# ADC_ADC_CFG_502C0000h register map
Vendor: Texas Instruments
Registers are 16-bit, read-write, reset values left out (the file's numbers can be read two ways) unless marked. A register's access mark holds for its fields unless they carry their own. Offsets are as the file gives them; [hi:lo] are bit positions; {n}, {i} and the like mark numbered series.

## ADC_CFG (part 2 of 3)
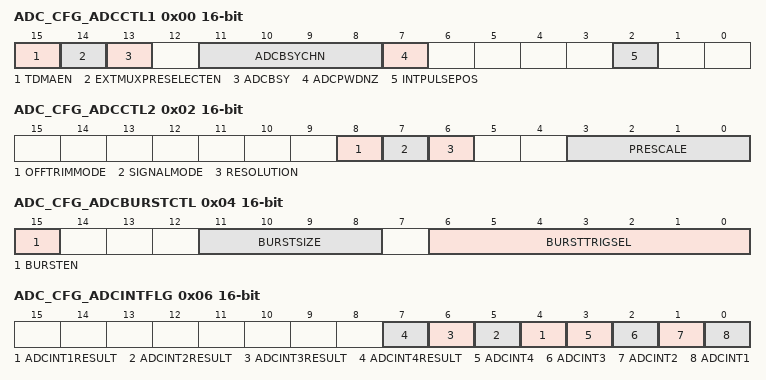
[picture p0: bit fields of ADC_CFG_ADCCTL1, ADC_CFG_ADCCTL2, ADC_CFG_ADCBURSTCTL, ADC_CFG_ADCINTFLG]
0x00 ADC_CFG_ADCCTL1 access per field — ADC Control 1 Register.
  [15] TDMAEN rw — Enable Alternate DMA Timings. This bit controls when the DMA is triggered. 0 DMA is triggered at the same time as the CPU interrupt 1 DMA is always triggered at tDMA regardless or whether the ADC is in early interrupt mode or late interrupt mode
  [14] EXTMUXPRESELECTEN rw — If th the ADC SOC sequence is deterministic, the ADCEXTMUX pins can be set earlier: at the end of the S+H window of the previous conversion instead of the beginning of the S+H window of the current conversion. This allows some of the external mux settling time to be pipelined with the previous conversion's conversion time. However, this will not work in the case where high-priority SOCs can arrive asynchronously. 0 ADCEXTMUX pins only change at beginning of S+H window 1 ADCEXTMUX pins are set after the end of S+H window based on pending SOCs
  [13] ADCBSY ro — ADC Busy. Set when ADC SOC is generated, cleared by hardware four ADC clocks after negative edge of S/H pulse. Used by the ADC state machine to determine if ADC is available to sample. 0 ADC is available to sample next channel 1 ADC is busy and cannot sample another channel
  [11:8] ADCBSYCHN ro — ADC Busy Channel. Set when an ADC Start of Conversion [SOC] is generated. When ADCBSY0:holds the value of the last converted SOC When ADCBSY1:reflects the SOC currently being processed 0h SOC0 is currently processing or was last SOC converted 1h SOC1 is currently processing or was last SOC converted 2h SOC2 is currently processing or was last SOC converted 3h SOC3 is currently processing or was last SOC converted 4h SOC4 is currently processing or was last SOC converted 5h SOC5 is currently processing or was last SOC converted 6h SOC6 is currently processing or was last SOC converted 7h SOC7 is currently processing or was last SOC converted 8h SOC8 is currently processing or was last SOC converted 9h SOC9 is currently processing or was last SOC converted Ah SOC10 is currently processing or was last SOC converted Bh SOC11 is currently processing or was last SOC converted Ch SOC12 is currently processing or was last SOC converted Dh SOC13 is currently processing or was last SOC converted Eh SOC14 is currently processing or was last SOC converted Fh SOC15 is currently processing or was last SOC converted
  [7] ADCPWDNZ rw — ADC Power Down [active low]. This bit controls the power up and power down of all the analog circuitry inside the analog core. 0 All analog circuitry inside the core is powered down 1 All analog circuitry inside the core is powered up
  [2] INTPULSEPOS rw — ADC Interrupt Pulse Position. 0 Interrupt pulse generation occurs when ADC begins conversion [at the end of the acquisition window] plus a number of SYSCLK cycles as specified in the ADCINTCYCLE.OFFSET register. 1 Interrupt pulse generation occurs at the end of the conversion, 1 cycle prior to the ADC result latching into its result register
0x02 ADC_CFG_ADCCTL2 — ADC Control 2 Register.
  [8] OFFTRIMMODE — ADC offset trim mode. 0 = Offset trim supplied by ADCOFFTRIM.OFFTRIM regardless of resolution or signal mode 1 = Offset trim for each combination of resolution, signalmode, and even or odd is supplied by a different field in ADCOFFTRIM, ADCOFFTRIM2, or ADCOFFTRIM3
  [7] SIGNALMODE — SOC Signaling Mode. Selects the input mode of the converter. Use the AdcSetMode function to change the signal mode. 0 Single-ended 1 Differential
  [6] RESOLUTION — SOC Conversion Resolution. Selects the resolution of the converter. Use the AdcSetMode function to change the resolution. 0 12-bit resolution
  [3:0] PRESCALE — ADC Clock Prescaler. 0000 ADCCLK = Input Clock / 1.0 0001 Invalid 0010 ADCCLK = Input Clock / 2.0 0011 ADCCLK = Input Clock / 2.5 0100 ADCCLK = Input Clock / 3.0 0101 ADCCLK = Input Clock / 3.5 0110 ADCCLK = Input Clock / 4.0 0111 ADCCLK = Input Clock / 4.5 1000 ADCCLK = Input Clock / 5.0 1001 ADCCLK = Input Clock / 5.5 1010 ADCCLK = Input Clock / 6.0 1011 ADCCLK = Input Clock / 6.5 1100 ADCCLK = Input Clock / 7.0 1101 ADCCLK = Input Clock / 7.5 1110 ADCCLK = Input Clock / 8.0 1111 ADCCLK = Input Clock / 8.5
0x04 ADC_CFG_ADCBURSTCTL — ADC Burst Control Register.
  [15] BURSTEN — SOC Burst Mode Enable. This bit enables the SOC Burst Mode of operation. 0 Burst mode is disabled. 1 Burst mode is enabled.
  [11:8] BURSTSIZE — SOC Burst Size Select. This bit field determines how many SOCs are converted when a burst conversion sequence is started. The first SOC converted is defined by the round robin pointer, which is advanced as each SOC is converted. 0h 1 SOC converted 1h 2 SOCs converted 2h 3 SOCs converted 3h 4 SOCs converted 4h 5 SOCs converted 5h 6 SOCs converted 6h 7 SOCs converted 7h 8 SOCs converted 8h 9 SOCs converted 9h 10 SOCs converted Ah 11 SOCs converted Bh 12 SOCs converted Ch 13 SOCs converted Dh 14 SOCs converted Eh 15 SOCs converted Fh 16 SOCs converted Note: If the burst causes SOCs to be set for conversion that were already pending, the corresponding bits in the ADCSOCOVF register will be set.
  [6:0] BURSTTRIGSEL — SOC Burst Trigger Source Select. Configures which trigger will start a burst conversion sequence.Note: SOCFRC1 register can always be used to software trigger SOCs in addition to any hardware trigger configuration. 00h BURSTTRIG0 - Software only 01h BURSTTRIG1 - RTI0 Timer 02h BURSTTRIG2 - RTI1 Timer 03h BURSTTRIG3 - RTI2 Timer 04h BURSTTRIG4 - RTI3 Timer 05h BURSTTRIG5 - InputXBAR.Out[5] 06h BURSTTRIG6 - spare 07h BURSTTRIG7 - spare 08h BURSTTRIG8 - EPWM0, ADCSOCA 09h BURSTTRIG9 - EPWM0, ADCSOCB 0Ah BURSTTRIG10 - EPWM1, ADCSOCA 0Bh BURSTTRIG11 - EPWM1, ADCSOCB 0Ch BURSTTRIG12 - EPWM2, ADCSOCA 0Dh BURSTTRIG13 - EPWM2, ADCSOCB 0Eh BURSTTRIG14 - EPWM3, ADCSOCA 0Fh BURSTTRIG15 - EPWM3, ADCSOCB .... EPWM4 to EPWM27 40h BURSTTRIG64 - EPWM28, ADCSOCA 41h BURSTTRIG65 - EPWM28, ADCSOCB 42h BURSTTRIG66 - EPWM29, ADCSOCA 43h BURSTTRIG67 - EPWM29, ADCSOCB 44h BURSTTRIG68 - EPWM30, ADCSOCA 45h BURSTTRIG69 - EPWM30, ADCSOCB 46h BURSTTRIG70 - EPWM31, ADCSOCA 47h BURSTTRIG71 - EPWM31, ADCSOCB 48h BURSTTRIG72 - ECAP0, TRIGOUT .... ECAP1 to ECAP8 51h BURSTTRIG81 - ECAP9, TRIGOUT 52h BURSTTRIG82 - ECAP10, TRIGOUT .... 57h BURSTTRIG73 - ECAP15, TRIGOUT 58h BURSTTRIG1 - RTI4 Timer 59h BURSTTRIG1 - RTI5 Timer 5Ah BURSTTRIG1 - RTI6 Timer 5Bh BURSTTRIG1 - RTI7 Timer
0x06 ADC_CFG_ADCINTFLG ro — ADC Interrupt Flag Register.
  [n+3] ADCINT{n}RESULT (n=1..4) — ADC Interrupt {n} Results Ready Flag. This flag is set when the conversions results associated with ADCINT{n} latch into the corresponding results register. 0 Conversion results have not latched 1 Conversion results have latched This flag can be used in an ISR that is entered in early interrupt mode to ensure that the corresponding results are ready before proceeding to read the result register. This flag can be cleared via the ACK bit in the ADCINTFLGCLR that also clears the ADCINT{n} flag. In case results latch and this flag is already set, the corresponding flag in ADCINTOVF is NOT set. This flag does NOT have to be cleared in order for ADCINT ISRs to propagate to the PIE. In case the associated SOC is associated with a PPB or PPBs, the flag will not be set until all associated PPB results latch.
  [3] ADCINT4 — ADC Interrupt 4 Flag. Reading these flags indicates if the associated ADCINT pulse was generated since the last clear. 0 No ADC interrupt pulse generated 1 ADC interrupt pulse generated If the ADC interrupt is placed in continue to interrupt mode [INTSELxNy register] then further interrupt pulses are generated whenever a selected EOC event occurs even if the flag bit is set. If the continuous mode is not enabled, then no further interrupt pulses are generated until the user clears this flag bit using the ADCINFLGCLR register. Rather, an ADC interrupt overflow event occurs in the ADCINTOVF register.
  [2] ADCINT3 — ADC Interrupt 3 Flag. Reading these flags indicates if the associated ADCINT pulse was generated since the last clear. 0 No ADC interrupt pulse generated 1 ADC interrupt pulse generated If the ADC interrupt is placed in continue to interrupt mode [INTSELxNy register] then further interrupt pulses are generated whenever a selected EOC event occurs even if the flag bit is set. If the continuous mode is not enabled, then no further interrupt pulses are generated until the user clears this flag bit using the ADCINTFLGCLR register. Rather, an ADC interrupt overflow event occurs in the ADCINTOVF register.
  [1] ADCINT2 — ADC Interrupt 2 Flag. Reading these flags indicates if the associated ADCINT pulse was generated since the last clear. 0 No ADC interrupt pulse generated 1 ADC interrupt pulse generated If the ADC interrupt is placed in continue to interrupt mode [INTSELxNy register] then further interrupt pulses are generated whenever a selected EOC event occurs even if the flag bit is set. If the continuous mode is not enabled, then no further interrupt pulses are generated until the user clears this flag bit using the ADCINTFLGCLR register. Rather, an ADC interrupt overflow event occurs in the ADCINTOVF register.
  [0] ADCINT1 — ADC Interrupt 1 Flag. Reading these flags indicates if the associated ADCINT pulse was generated since the last clear. 0 No ADC interrupt pulse generated 1 ADC interrupt pulse generated If the ADC interrupt is placed in continue to interrupt mode [INTSELxNy register] then further interrupt pulses are generated whenever a selected EOC event occurs even if the flag bit is set. If the continuous mode is not enabled, then no further interrupt pulses are generated until the user clears this flag bit using the ADCINTFLGCLR register. Rather, an ADC interrupt overflow event occurs in the ADCINTOVF register.
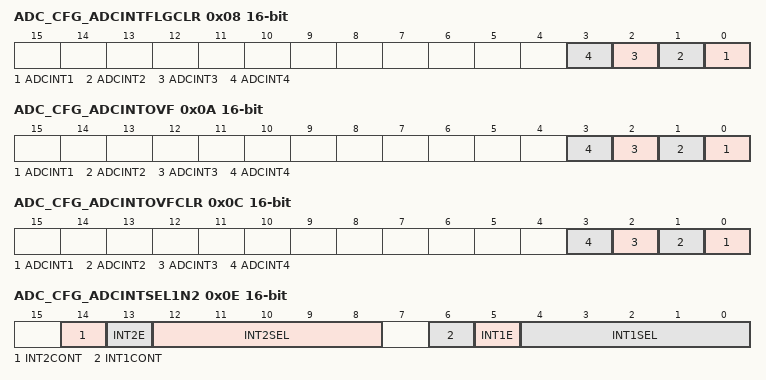
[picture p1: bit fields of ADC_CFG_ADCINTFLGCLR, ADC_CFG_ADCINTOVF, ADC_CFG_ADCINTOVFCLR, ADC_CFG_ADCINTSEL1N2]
0x08 ADC_CFG_ADCINTFLGCLR access not given — ADC Interrupt Flag Clear Register.
  [n-1] ADCINT{n} (n=1..4) — ADC Interrupt {n} Flag Clear. Reads return 0. 0 No action 1 Clears respective flag bit in the ADCINTFLG register. If software sets the clear bit on the same cycle that hardware is trying to set the flag bit, then hardware has priority and the overflow bit will not be set (access R/W1TS)
0x0A ADC_CFG_ADCINTOVF ro — ADC Interrupt Overflow Register.
  [n-1] ADCINT{n} (n=1..4) — ADC Interrupt {n} Overflow Flags Indicates if an overflow occurred when generating ADCINT pulses. If the respective ADCINTFLG bit is set and a selected additional EOC trigger is generated, then an overflow condition occurs. 0 No ADC interrupt overflow event detected. 1 ADC Interrupt overflow event detected. The overflow bit does not care about the continuous mode bit state. An overflow condition is generated irrespective of this mode selection.
0x0C ADC_CFG_ADCINTOVFCLR access not given — ADC Interrupt Overflow Clear Register.
  [n-1] ADCINT{n} (n=1..4) — ADC Interrupt {n} Overflow Clear Bits 0 No action. 1 Clears the respective overflow bit in the ADCINTOVF register. If software tries to set this bit on the same clock cycle that hardware tries to set the overflow bit in the ADCINTOVF register, then hardware has priority and the ADCINTOVF bit will be set. (access R/W1TS)
0x0E ADC_CFG_ADCINTSEL1N2 — ADC Interrupt 1 and 2 Selection Register.
  [14] INT2CONT — ADCINT2 Continue to Interrupt Mode 0 No further ADCINT2 pulses are generated until ADCINT2 flag [in ADCINTFLG register] is cleared by user. 1 ADCINT2 pulses are generated whenever an EOC pulse is generated irrespective of whether the flag bit is cleared or not.
  [13] INT2E — ADCINT2 Interrupt Enable 0 ADCINT2 is disabled 1 ADCINT2 is enabled
  [12:8] INT2SEL — ADCINT2 EOC Source Select 00h EOC0 is trigger for ADCINT2 01h EOC1 is trigger for ADCINT2 02h EOC2 is trigger for ADCINT2 03h EOC3 is trigger for ADCINT2 04h EOC4 is trigger for ADCINT2 05h EOC5 is trigger for ADCINT2 06h EOC6 is trigger for ADCINT2 07h EOC7 is trigger for ADCINT2 08h EOC8 is trigger for ADCINT2 09h EOC9 is trigger for ADCINT2 0Ah EOC10 is trigger for ADCINT2 0Bh EOC11 is trigger for ADCINT2 0Ch EOC12 is trigger for ADCINT2 0Dh EOC13 is trigger for ADCINT2 0Eh EOC14 is trigger for ADCINT2 0Fh EOC15 is trigger for ADCINT2 10h OSINT1 is trigger for ADCINT2 11h OSINT2 is trigger for ADCINT2 12h OSINT3 is trigger for ADCINT2 13h OSINT4 is trigger for ADCINT2
  [6] INT1CONT — ADCINT1 Continue to Interrupt Mode 0 No further ADCINT1 pulses are generated until ADCINT1 flag [in ADCINTFLG register] is cleared by user. 1 ADCINT1 pulses are generated whenever an EOC pulse is generated irrespective of whether the flag bit is cleared or not.
  [5] INT1E — ADCINT1 Interrupt Enable 0 ADCINT1 is disabled 1 ADCINT1 is enabled
  [4:0] INT1SEL — ADCINT1 EOC Source Select 00h EOC0 is trigger for ADCINT1 01h EOC1 is trigger for ADCINT1 02h EOC2 is trigger for ADCINT1 03h EOC3 is trigger for ADCINT1 04h EOC4 is trigger for ADCINT1 05h EOC5 is trigger for ADCINT1 06h EOC6 is trigger for ADCINT1 07h EOC7 is trigger for ADCINT1 08h EOC8 is trigger for ADCINT1 09h EOC9 is trigger for ADCINT1 0Ah EOC10 is trigger for ADCINT1 0Bh EOC11 is trigger for ADCINT1 0Ch EOC12 is trigger for ADCINT1 0Dh EOC13 is trigger for ADCINT1 0Eh EOC14 is trigger for ADCINT1 0Fh EOC15 is trigger for ADCINT1 10h OSINT1 is trigger for ADCINT1 11h OSINT2 is trigger for ADCINT1 12h OSINT3 is trigger for ADCINT1 13h OSINT4 is trigger for ADCINT1
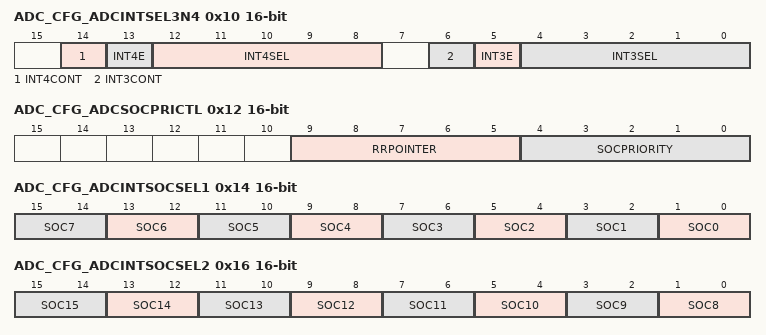
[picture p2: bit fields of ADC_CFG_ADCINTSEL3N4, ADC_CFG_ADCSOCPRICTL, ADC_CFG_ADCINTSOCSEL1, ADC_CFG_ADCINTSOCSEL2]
0x10 ADC_CFG_ADCINTSEL3N4 — ADC Interrupt 3 and 4 Selection Register.
  [14] INT4CONT — ADCINT4 Continue to Interrupt Mode 0 No further ADCINT4 pulses are generated until ADCINT4 flag [in ADCINTFLG register] is cleared by user. 1 ADCINT4 pulses are generated whenever an EOC pulse is generated irrespective of whether the flag bit is cleared or not.
  [13] INT4E — ADCINT4 Interrupt Enable 0 ADCINT4 is disabled 1 ADCINT4 is enabled
  [12:8] INT4SEL — ADCINT4 EOC Source Select 00h EOC0 is trigger for ADCINT4 01h EOC1 is trigger for ADCINT4 02h EOC2 is trigger for ADCINT4 03h EOC3 is trigger for ADCINT4 04h EOC4 is trigger for ADCINT4 05h EOC5 is trigger for ADCINT4 06h EOC6 is trigger for ADCINT4 07h EOC7 is trigger for ADCINT4 08h EOC8 is trigger for ADCINT4 09h EOC9 is trigger for ADCINT4 0Ah EOC10 is trigger for ADCINT4 0Bh EOC11 is trigger for ADCINT4 0Ch EOC12 is trigger for ADCINT4 0Dh EOC13 is trigger for ADCINT4 0Eh EOC14 is trigger for ADCINT4 0Fh EOC15 is trigger for ADCINT4 10hOSINT1 is trigger for ADCINT4 11hOSINT2 is trigger for ADCINT4 12hOSINT3 is trigger for ADCINT4 13hOSINT4 is trigger for ADCINT4
  [6] INT3CONT — ADCINT3 Continue to Interrupt Mode 0 No further ADCINT3 pulses are generated until ADCINT3 flag [in ADCINTFLG register] is cleared by user. 1 ADCINT3 pulses are generated whenever an EOC pulse is generated irrespective of whether the flag bit is cleared or not.
  [5] INT3E — ADCINT3 Interrupt Enable 0 ADCINT3 is disabled 1 ADCINT3 is enabled
  [4:0] INT3SEL — ADCINT3 EOC Source Select 00h EOC0 is trigger for ADCINT3 01h EOC1 is trigger for ADCINT3 02h EOC2 is trigger for ADCINT3 03h EOC3 is trigger for ADCINT3 04h EOC4 is trigger for ADCINT3 05h EOC5 is trigger for ADCINT3 06h EOC6 is trigger for ADCINT3 07h EOC7 is trigger for ADCINT3 08h EOC8 is trigger for ADCINT3 09h EOC9 is trigger for ADCINT3 0Ah EOC10 is trigger for ADCINT3 0Bh EOC11 is trigger for ADCINT3 0Ch EOC12 is trigger for ADCINT3 0Dh EOC13 is trigger for ADCINT3 0Eh EOC14 is trigger for ADCINT3 0Fh EOC15 is trigger for ADCINT3 10h OSINT1 is trigger for ADCINT3 11h OSINT2 is trigger for ADCINT3 12h OSINT3 is trigger for ADCINT3 13h OSINT4 is trigger for ADCINT3
0x12 ADC_CFG_ADCSOCPRICTL access per field — ADC SOC Priority Control Register.
  [9:5] RRPOINTER ro — Round Robin Pointer. Holds the value of the last converted round robin SOCx to be used by the round robin scheme to determine order of conversions. 00h SOC0 was last round robin SOC to convert, SOC1 is highest round robin priority. 01h SOC1 was last round robin SOC to convert, SOC2 is highest round robin priority. 02h SOC2 was last round robin SOC to convert, SOC3 is highest round robin priority. 03h SOC3 was last round robin SOC to convert, SOC4 is highest round robin priority. 04h SOC4 was last round robin SOC to convert, SOC5 is highest round robin priority. 05h SOC5 was last round robin SOC to convert, SOC6 is highest round robin priority. 06h SOC6 was last round robin SOC to convert, SOC7 is highest round robin priority. 07h SOC7 was last round robin SOC to convert, SOC8 is highest round robin priority. 08h SOC8 was last round robin SOC to convert, SOC9 is highest round robin priority. 09h SOC9 was last round robin SOC to convert, SOC10 is highest round robin priority. 0Ah SOC10 was last round robin SOC to convert, SOC11 is highest round robin priority. 0Bh SOC11 was last round robin SOC to convert, SOC12 is highest round robin priority. 0Ch SOC12 was last round robin SOC to convert, SOC13 is highest round robin priority. 0Dh SOC13 was last round robin SOC to convert, SOC14 is highest round robin priority. 0Eh SOC14 was last round robin SOC to convert, SOC15 is highest round robin priority. 0Fh SOC15 was last round robin SOC to convert, SOC0 is highest round robin priority. 10h Reset value to indicate no SOC has been converted. SOC0 is highest round robin priority. Set to this value when the ADC module is reset by SOFTPRES or when the ADCSOCPRICTL register is written. In the latter case, if a conversion is currently in progress, it will complete and then the new priority will take effect. Others Invalid value.
  [4:0] SOCPRIORITY rw — SOC Priority Determines the cutoff point for priority mode and round robin arbitration for SOCx 00h SOC priority is handled in round robin mode for all channels. 01h SOC0 is high priority, rest of channels are in round robin mode. 02h SOC0-SOC1 are high priority, SOC2-SOC15 are in round robin mode. 03h SOC0-SOC2 are high priority, SOC3-SOC15 are in round robin mode. 04h SOC0-SOC3 are high priority, SOC4-SOC15 are in round robin mode. 05h SOC0-SOC4 are high priority, SOC5-SOC15 are in round robin mode. 06h SOC0-SOC5 are high priority, SOC6-SOC15 are in round robin mode. 07h SOC0-SOC6 are high priority, SOC7-SOC15 are in round robin mode. 08h SOC0-SOC7 are high priority, SOC8-SOC15 are in round robin mode. 09h SOC0-SOC8 are high priority, SOC9-SOC15 are in round robin mode. 0Ah SOC0-SOC9 are high priority, SOC10-SOC15 are in round robin mode. 0Bh SOC0-SOC10 are high priority, SOC11-SOC15 are in round robin mode. 0Ch SOC0-SOC11 are high priority, SOC12-SOC15 are in round robin mode. 0Dh SOC0-SOC12 are high priority, SOC13-SOC15 are in round robin mode. 0Eh SOC0-SOC13 are high priority, SOC14-SOC15 are in round robin mode. 0Fh SOC0-SOC14 are high priority, SOC15 is in round robin mode. 10h All SOCs are in high priority mode, arbitrated by SOC number. Others Invalid selection.
0x14 ADC_CFG_ADCINTSOCSEL1 — ADC Interrupt SOC Selection 1 Register.
  [2n+1:2n] SOC{n} (n=0..7) — SOC{n} ADC Interrupt Trigger Select. Selects which, if any, ADCINT triggers SOC{n}. The trigger selected in this field is in addition to the TRIGSEL field in the ADCSOCxCTL register. 00 No ADCINT will trigger SOC{n}. TRIGSEL field alone determines SOC0 trigger. 01 ADCINT1 will trigger SOC{n}. 10 ADCINT2 will trigger SOC{n}. 11 Invalid selection.
0x16 ADC_CFG_ADCINTSOCSEL2 — ADC Interrupt SOC Selection 2 Register.
  [2n-15:2n-16] SOC{n} (n=8..15) — SOC{n} ADC Interrupt Trigger Select. Selects which, if any, ADCINT triggers SOC{n}. The trigger selected in this field is in addition to the TRIGSEL field in the ADCSOCxCTL register. 00 No ADCINT will trigger SOC{n}. TRIGSEL field alone determines SOC0 trigger. 01 ADCINT1 will trigger SOC{n}. 10 ADCINT2 will trigger SOC{n}. 11 Invalid selection.
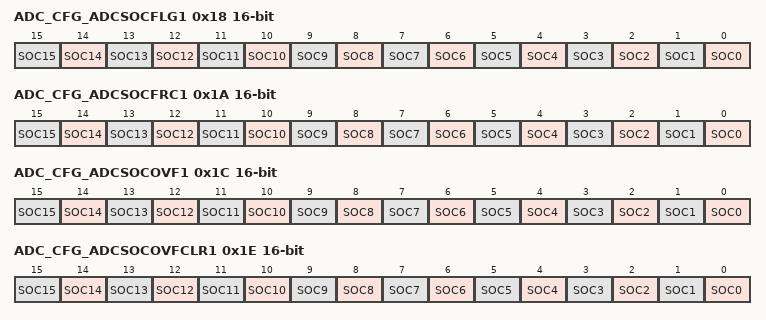
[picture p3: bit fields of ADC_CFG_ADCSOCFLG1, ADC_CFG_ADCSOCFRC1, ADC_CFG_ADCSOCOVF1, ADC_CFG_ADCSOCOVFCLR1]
0x18 ADC_CFG_ADCSOCFLG1 ro — ADC SOC Flag 1 Register.
  [n] SOC{n} (n=0..15) — SOC{n} Start of Conversion Flag. Indicates the state of SOC{n} conversions. 0 No sample pending for SOC{n}. 1 Trigger has been received and sample is pending for SOC{n}. This bit will be automatically cleared when the SOC{n} conversion is started. If contention exists where this bit receives both a request to set and a request to clear on the same cycle, regardless of the source of either, this bit will be set and the request to clear will be ignored. In this case the overflow bit in the ADCSOCOVF1 register will not be affected regardless of whether this bit was previously set or not.
0x1A ADC_CFG_ADCSOCFRC1 access not given — ADC SOC Force 1 Register.
  [n] SOC{n} (n=0..15) — SOC{n} Force Start of Conversion Bit. Writing a 1 will force to 1 the SOC{n} flag in the ADCSOCFLG1 register. This can be used to initiate a software initiated conversion. Writes of 0 are ignored. This bit will always read as a 0. 0 No action. 1 Force SOC{n} flag bit to 1. This will cause a conversion to start once priority is given to SOC{n}. If software tries to set this bit on the same clock cycle that hardware tries to clear the SOC{n} bit in the ADCSOCFLG1 register, then software has priority and the ADCSOCFLG1 bit will be set. In this case the overflow bit in the ADCSOCOVF1 register will not be affected regardless of whether the ADCSOCFLG1 bit was previously set or not. (access R/W1TS)
0x1C ADC_CFG_ADCSOCOVF1 ro — ADC SOC Overflow 1 Register.
  [n] SOC{n} (n=0..15) — SOC{n} Start of Conversion Overflow Flag. Indicates an SOC{n} event was generated in hardware while an existing SOC{n} event was already pending. 0 No SOC{n} event overflow. 1 SOC{n} event overflow. An overflow condition does not stop SOC{n} events from being processed. It simply is an indication that a hardware trigger was missed. A write to the ADCSOCFRC1 register does not effect this bit.
0x1E ADC_CFG_ADCSOCOVFCLR1 access not given — ADC SOC Overflow Clear 1 Register.
  [n] SOC{n} (n=0..15) — SOC{n} Clear Start of Conversion Overflow Bit. Writing a 1 will clear the SOC{n} overflow flag in the ADCSOCOVF1 register. Writes of 0 are ignored. Reads will always return a 0. 0 No action. 1 Clear SOC{n} overflow flag. If software tries to set this bit on the same clock cycle that hardware tries to set the overflow bit in the ADCSOCOVF1 register, then hardware has priority and the ADCSOCOVF1 bit will be set.. (access R/W1TS)
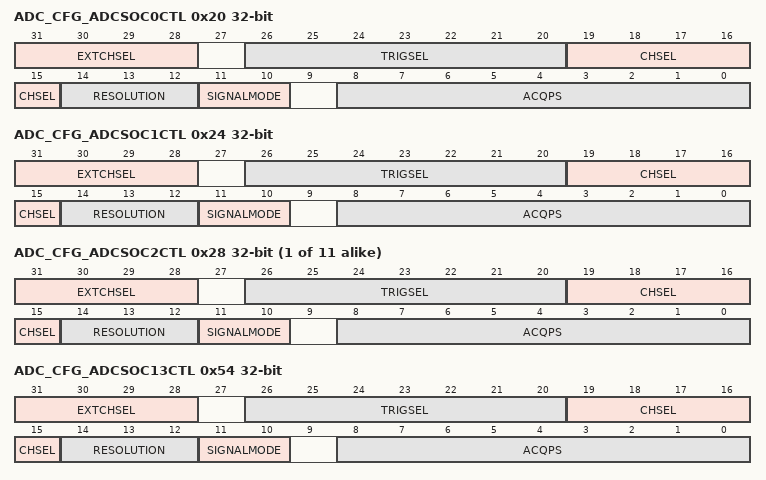
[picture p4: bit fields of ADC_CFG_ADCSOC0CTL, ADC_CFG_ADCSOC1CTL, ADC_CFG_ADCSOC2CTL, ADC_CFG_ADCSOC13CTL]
0x20 ADC_CFG_ADCSOC0CTL 32-bit access per field — ADC SOC0 Control Register.
  [31:28] EXTCHSEL rw — SOC0 External Channel Mux Select. Selects the external mux combination to output when SOC0 is received by the ADC. Some or all of the ADCEXTMUX lines can be enabled via the device GPIO mux to control an external analog mux.
  [26:20] TRIGSEL rw — SOC0 Trigger Source Select. Along with the SOC0 field in the ADCINTSOCSEL1 register, this bit field configures which trigger will set the SOC0 flag in the ADCSOCFLG1 register to initiate a conversion to start once priority is given to it. Note: SOCFRC1 register can always be used to software trigger SOCs in addition to any hardware trigger configuration. 00h ADCTRIG0 - Software only 01h ADCTRIG1 - RTI0 Timer 02h ADCTRIG2 - RTI1 Timer 03h ADCTRIG3 - RTI2 Timer 04h ADCTRIG4 - RTI3 Timer 05h ADCTRIG5 - InputXBAR.Out[5] 06h ADCTRIG6 - spare 07h ADCTRIG7 - spare 08h ADCTRIG8 - EPWM0, ADCSOCA 09h ADCTRIG9 - EPWM0, ADCSOCB 0Ah ADCTRIG10 - EPWM1, ADCSOCA 0Bh ADCTRIG11 - EPWM1, ADCSOCB 0Ch ADCTRIG12 - EPWM2, ADCSOCA 0Dh ADCTRIG13 - EPWM2, ADCSOCB 0Eh ADCTRIG14 - EPWM3, ADCSOCA 0Fh ADCTRIG15 - EPWM3, ADCSOCB .... EPWM4 to EPWM27 40h ADCTRIG64 - EPWM28, ADCSOCA 41h ADCTRIG65 - EPWM28, ADCSOCB 42h ADCTRIG66 - EPWM29, ADCSOCA 43h ADCTRIG67 - EPWM29, ADCSOCB 44h ADCTRIG68 - EPWM30, ADCSOCA 45h ADCTRIG69 - EPWM30, ADCSOCB 46h ADCTRIG70 - EPWM31, ADCSOCA 47h ADCTRIG71 - EPWM31, ADCSOCB 48h ADCTRIG72 - ECAP0, TRIGOUT .... ECAP1 to ECAP8 51h ADCTRIG81 - ECAP9, TRIGOUT 52h ADCTRIG82 - ECAP10, TRIGOUT .... 57h ADCTRIG87 - ECAP15, TRIGOUT 58h ADCTRIG88 - RTI4 Timer 59h ADCTRIG89 - RTI5 Timer 5Ah ADCTRIG90 - RTI6 Timer 5Bh ADCTRIG91 - RTI7 Timer .... 7Fh ADCTRIG127 - REP2TRIG - these are not external trigger signals on the ADC IP port. We need to configure them for internal selection of repeater triggers.
  [19:15] CHSEL rw — SOC0 Channel Select. Selects the channel to be converted when SOC0 is received by the ADC. Single-ended Signaling Mode [SIGNALMODE = 0]: 00h ADCIN0 01h ADCIN1 02h ADCIN2 03h ADCIN3 04h ADCIN405h ADCIN5 Differential Signaling Mode [SIGNALMODE = 1]: 00h ADCIN0 [non-inverting] and ADCIN1 [inverting] 01h ADCIN0 [non-inverting] and ADCIN1 [inverting] 02h ADCIN2 [non-inverting] and ADCIN3 [inverting] 03h ADCIN2 [non-inverting] and ADCIN3 [inverting] 04h ADCIN4 [non-inverting] and ADCIN5 [inverting] 05h ADCIN4 [non-inverting] and ADCIN5 [inverting]
  [14:12] RESOLUTION ro — Placeholder for per-SOC resolution
  [11:10] SIGNALMODE ro — Placeholder for per-SOC signal mode
  [8:0] ACQPS rw — SOC0 Acquisition Prescale. Controls the sample and hold window for this SOC. 000h Reserved 001h Reserved 002h Sample window is 3 system clock cycles wide 003h Sample window is 4 system clock cycles wide ... 1FFh Sample window is 512 system clock cycles wide The configured acquisition time must be at least as long as one ADCCLK cycle for correct ADC operation. The configured acquisition time must also be at least 3 SYSCLK cycles long. The device datasheet will also specify a minimum sample and hold window duration.
0x24 ADC_CFG_ADCSOC1CTL 32-bit access per field — ADC SOC1 Control Register.
  [31:28] EXTCHSEL rw — SOC1 External Channel Mux Select. Selects the external mux combination to output when SOC1 is received by the ADC. Some or all of the ADCEXTMUX lines can be enabled via the device GPIO mux to control an external analog mux.
  [26:20] TRIGSEL rw — SOC1 Trigger Source Select. Along with the SOC1 field in the ADCINTSOCSEL1 register, this bit field configures which trigger will set the SOC1 flag in the ADCSOCFLG1 register to initiate a conversion to start once priority is given to it. Note: SOCFRC1 register can always be used to software trigger SOCs in addition to any hardware trigger configuration. 00h ADCTRIG0 - Software only 01h ADCTRIG1 - RTI0 Timer 02h ADCTRIG2 - RTI1 Timer 03h ADCTRIG3 - RTI2 Timer 04h ADCTRIG4 - RTI3 Timer 05h ADCTRIG5 - InputXBAR.Out[5] 06h ADCTRIG6 - spare 07h ADCTRIG7 - spare 08h ADCTRIG8 - EPWM0, ADCSOCA 09h ADCTRIG9 - EPWM0, ADCSOCB 0Ah ADCTRIG10 - EPWM1, ADCSOCA 0Bh ADCTRIG11 - EPWM1, ADCSOCB 0Ch ADCTRIG12 - EPWM2, ADCSOCA 0Dh ADCTRIG13 - EPWM2, ADCSOCB 0Eh ADCTRIG14 - EPWM3, ADCSOCA 0Fh ADCTRIG15 - EPWM3, ADCSOCB .... EPWM4 to EPWM27 40h ADCTRIG64 - EPWM28, ADCSOCA 41h ADCTRIG65 - EPWM28, ADCSOCB 42h ADCTRIG66 - EPWM29, ADCSOCA 43h ADCTRIG67 - EPWM29, ADCSOCB 44h ADCTRIG68 - EPWM30, ADCSOCA 45h ADCTRIG69 - EPWM30, ADCSOCB 46h ADCTRIG70 - EPWM31, ADCSOCA 47h ADCTRIG71 - EPWM31, ADCSOCB 48h ADCTRIG72 - ECAP0, TRIGOUT .... ECAP1 to ECAP8 51h ADCTRIG81 - ECAP9, TRIGOUT 52h ADCTRIG82 - ECAP10, TRIGOUT .... 57h ADCTRIG87 - ECAP15, TRIGOUT 58h ADCTRIG88 - RTI4 Timer 59h ADCTRIG89 - RTI5 Timer 5Ah ADCTRIG90 - RTI6 Timer 5Bh ADCTRIG91 - RTI7 Timer .... 7Fh ADCTRIG127 - REP2TRIG - these are not external trigger signals on the ADC IP port. We need to configure them for internal selection of repeater triggers.
  [19:15] CHSEL rw — SOC1 Channel Select. Selects the channel to be converted when SOC1 is received by the ADC. Single-ended Signaling Mode [SIGNALMODE = 0]: 00h: ADCIN0 01h: ADCIN1 02h: ADCIN2 03h ADCIN3 04h ADCIN4 05h ADCIN5 Differential Signaling Mode [SIGNALMODE = 1]: 00h: ADCIN0 [non-inverting] and ADCIN1 [inverting] 01h: ADCIN0 [non-inverting] and ADCIN1 [inverting] 02h: ADCIN2 [non-inverting] and ADCIN3 [inverting] 03h: ADCIN2 [non-inverting] and ADCIN3 [inverting] 04h: ADCIN4 [non-inverting] and ADCIN5 [inverting] 05h ADCIN4 [non-inverting] and ADCIN5 [inverting]
  [14:12] RESOLUTION ro — Placeholder for per-SOC resolution
  [11:10] SIGNALMODE ro — Placeholder for per-SOC signal mode
  [8:0] ACQPS rw — SOC1 Acquisition Prescale. Controls the sample and hold window for this SOC. 000h Reserved 001h Reserved 002h Sample window is 3 system clock cycles wide 003h Sample window is 4 system clock cycles wide ... 1FFh Sample window is 512 system clock cycles wide The configured acquisition time must be at least as long as one ADCCLK cycle for correct ADC operation. The configured acquisition time must also be at least 3 SYSCLK cycles long. The device datasheet will also specify a minimum sample and hold window duration.
{0x20+4i} ADC_CFG_ADCSOC{i}CTL 32-bit access per field (i=2..12) — ADC SOC{i} Control Register.
  [31:28] EXTCHSEL rw — SOC{i} External Channel Mux Select. Selects the external mux combination to output when SOC{i} is received by the ADC. Some or all of the ADCEXTMUX lines can be enabled via the device GPIO mux to control an external analog mux.
  [26:20] TRIGSEL rw — SOC{i} Trigger Source Select. Along with the SOC{i} field in the ADCINTSOCSEL1 register, this bit field configures which trigger will set the SOC{i} flag in the ADCSOCFLG1 register to initiate a conversion to start once priority is given to it. Note: SOCFRC1 register can always be used to software trigger SOCs in addition to any hardware trigger configuration. 00h ADCTRIG0 - Software only 01h ADCTRIG1 - RTI0 Timer 02h ADCTRIG2 - RTI1 Timer 03h ADCTRIG3 - RTI2 Timer 04h ADCTRIG4 - RTI3 Timer 05h ADCTRIG5 - InputXBAR.Out[5] 06h ADCTRIG6 - spare 07h ADCTRIG7 - spare 08h ADCTRIG8 - EPWM0, ADCSOCA 09h ADCTRIG9 - EPWM0, ADCSOCB 0Ah ADCTRIG10 - EPWM1, ADCSOCA 0Bh ADCTRIG11 - EPWM1, ADCSOCB 0Ch ADCTRIG12 - EPWM2, ADCSOCA 0Dh ADCTRIG13 - EPWM2, ADCSOCB 0Eh ADCTRIG14 - EPWM3, ADCSOCA 0Fh ADCTRIG15 - EPWM3, ADCSOCB .... EPWM4 to EPWM27 40h ADCTRIG64 - EPWM28, ADCSOCA 41h ADCTRIG65 - EPWM28, ADCSOCB 42h ADCTRIG66 - EPWM29, ADCSOCA 43h ADCTRIG67 - EPWM29, ADCSOCB 44h ADCTRIG68 - EPWM30, ADCSOCA 45h ADCTRIG69 - EPWM30, ADCSOCB 46h ADCTRIG70 - EPWM31, ADCSOCA 47h ADCTRIG71 - EPWM31, ADCSOCB 48h ADCTRIG72 - ECAP0, TRIGOUT .... ECAP1 to ECAP8 51h ADCTRIG81 - ECAP9, TRIGOUT 52h ADCTRIG82 - ECAP10, TRIGOUT .... 57h ADCTRIG87 - ECAP15, TRIGOUT 58h ADCTRIG88 - RTI4 Timer 59h ADCTRIG89 - RTI5 Timer 5Ah ADCTRIG90 - RTI6 Timer 5Bh ADCTRIG91 - RTI7 Timer .... 7Fh ADCTRIG127 - REP2TRIG - these are not external trigger signals on the ADC IP port. We need to configure them for internal selection of repeater triggers.
  [19:15] CHSEL rw — SOC{i} Channel Select. Selects the channel to be converted when SOC{i} is received by the ADC. Single-ended Signaling Mode [SIGNALMODE = 0]: 00h ADCIN0 01h ADCIN1 02h ADCIN2 03h ADCIN3 ... 1Dh ADCIN29 1Eh ADCIN30 1Fh ADCIN31 Differential Signaling Mode [SIGNALMODE = 1]: 00h ADCIN0 [non-inverting] and ADCIN1 [inverting] 01h ADCIN0 [non-inverting] and ADCIN1 [inverting] 02h ADCIN2 [non-inverting] and ADCIN3 [inverting] 03h ADCIN2 [non-inverting] and ADCIN3 [inverting] 04h ADCIN4 [non-inverting] and ADCIN5 [inverting] 05h ADCIN4 [non-inverting] and ADCIN5 [inverting] ... 0Eh ADCIN26 [non-inverting] and ADCIN27 [inverting] 0Fh ADCIN26 [non-inverting] and ADCIN27 [inverting] 10h ADCIN28 [non-inverting] and ADCIN29 [inverting] 11h ADCIN28 [non-inverting] and ADCIN29 [inverting] 1Eh ADCIN30 [non-inverting] and ADCIN31 [inverting] 1Fh ADCIN30 [non-inverting] and ADCIN31 [inverting]
  [14:12] RESOLUTION ro — Placeholder for per-SOC resolution
  [11:10] SIGNALMODE ro — Placeholder for per-SOC signal mode
  [8:0] ACQPS rw — SOC{i} Acquisition Prescale. Controls the sample and hold window for this SOC. 000h Reserved 001h Reserved 002h Sample window is 3 system clock cycles wide 003h Sample window is 4 system clock cycles wide ... 1FFh Sample window is 512 system clock cycles wide The configured acquisition time must be at least as long as one ADCCLK cycle for correct ADC operation. The configured acquisition time must also be at least 3 SYSCLK cycles long. The device datasheet will also specify a minimum sample and hold window duration.
0x54 ADC_CFG_ADCSOC13CTL 32-bit access per field — ADC SOC13 Control Register.
  [31:28] EXTCHSEL rw — SOC13 External Channel Mux Select. Selects the exter
  [26:20] TRIGSEL rw — SOC13 Trigger Source Select. Along with the SOC13 field in the ADCINTSOCSEL1 register, this bit field configures which trigger will set the SOC13 flag in the ADCSOCFLG1 register to initiate a conversion to start once priority is given to it. Note: SOCFRC1 register can always be used to software trigger SOCs in addition to any hardware trigger configuration. 00h ADCTRIG0 - Software only 01h ADCTRIG1 - RTI0 Timer 02h ADCTRIG2 - RTI1 Timer 03h ADCTRIG3 - RTI2 Timer 04h ADCTRIG4 - RTI3 Timer 05h ADCTRIG5 - InputXBAR.Out[5] 06h ADCTRIG6 - spare 07h ADCTRIG7 - spare 08h ADCTRIG8 - EPWM0, ADCSOCA 09h ADCTRIG9 - EPWM0, ADCSOCB 0Ah ADCTRIG10 - EPWM1, ADCSOCA 0Bh ADCTRIG11 - EPWM1, ADCSOCB 0Ch ADCTRIG12 - EPWM2, ADCSOCA 0Dh ADCTRIG13 - EPWM2, ADCSOCB 0Eh ADCTRIG14 - EPWM3, ADCSOCA 0Fh ADCTRIG15 - EPWM3, ADCSOCB .... EPWM4 to EPWM27 40h ADCTRIG64 - EPWM28, ADCSOCA 41h ADCTRIG65 - EPWM28, ADCSOCB 42h ADCTRIG66 - EPWM29, ADCSOCA 43h ADCTRIG67 - EPWM29, ADCSOCB 44h ADCTRIG68 - EPWM30, ADCSOCA 45h ADCTRIG69 - EPWM30, ADCSOCB 46h ADCTRIG70 - EPWM31, ADCSOCA 47h ADCTRIG71 - EPWM31, ADCSOCB 48h ADCTRIG72 - ECAP0, TRIGOUT .... ECAP1 to ECAP8 51h ADCTRIG81 - ECAP9, TRIGOUT 52h ADCTRIG82 - ECAP10, TRIGOUT .... 57h ADCTRIG87 - ECAP15, TRIGOUT 58h ADCTRIG88 - RTI4 Timer 59h ADCTRIG89 - RTI5 Timer 5Ah ADCTRIG90 - RTI6 Timer 5Bh ADCTRIG91 - RTI7 Timer .... 7Fh ADCTRIG127 - REP2TRIG - these are not external trigger signals on the ADC IP port. We need to configure them for internal selection of repeater triggers.
  [19:15] CHSEL rw — SOC13 Channel Select. Selects the channel to be converted when SOC13 is received by the ADC. Single-ended Signaling Mode [SIGNALMODE = 0]: 00h ADCIN0 01h ADCIN1 02h ADCIN2 03h ADCIN3 ... 1Dh ADCIN29 1Eh ADCIN30 1Fh ADCIN31 Differential Signaling Mode [SIGNALMODE = 1]: 00h ADCIN0 [non-inverting] and ADCIN1 [inverting] 01h ADCIN0 [non-inverting] and ADCIN1 [inverting] 02h ADCIN2 [non-inverting] and ADCIN3 [inverting] 03h ADCIN2 [non-inverting] and ADCIN3 [inverting] 04h ADCIN4 [non-inverting] and ADCIN5 [inverting] 05h ADCIN4 [non-inverting] and ADCIN5 [inverting] ... 0Eh ADCIN26 [non-inverting] and ADCIN27 [inverting] 0Fh ADCIN26 [non-inverting] and ADCIN27 [inverting] 10h ADCIN28 [non-inverting] and ADCIN29 [inverting] 11h ADCIN28 [non-inverting] and ADCIN29 [inverting] 1Eh ADCIN30 [non-inverting] and ADCIN31 [inverting] 1Fh ADCIN30 [non-inverting] and ADCIN31 [inverting]
  [14:12] RESOLUTION ro — Placeholder for per-SOC resolution
  [11:10] SIGNALMODE ro — Placeholder for per-SOC signal mode
  [8:0] ACQPS rw — SOC13 Acquisition Prescale. Controls the sample and hold window for this SOC. 000h Reserved 001h Reserved 002h Sample window is 3 system clock cycles wide 003h Sample window is 4 system clock cycles wide ... 1FFh Sample window is 512 system clock cycles wide The configured acquisition time must be at least as long as one ADCCLK cycle for correct ADC operation. The configured acquisition time must also be at least 3 SYSCLK cycles long. The device datasheet will also specify a minimum sample and hold window duration.
